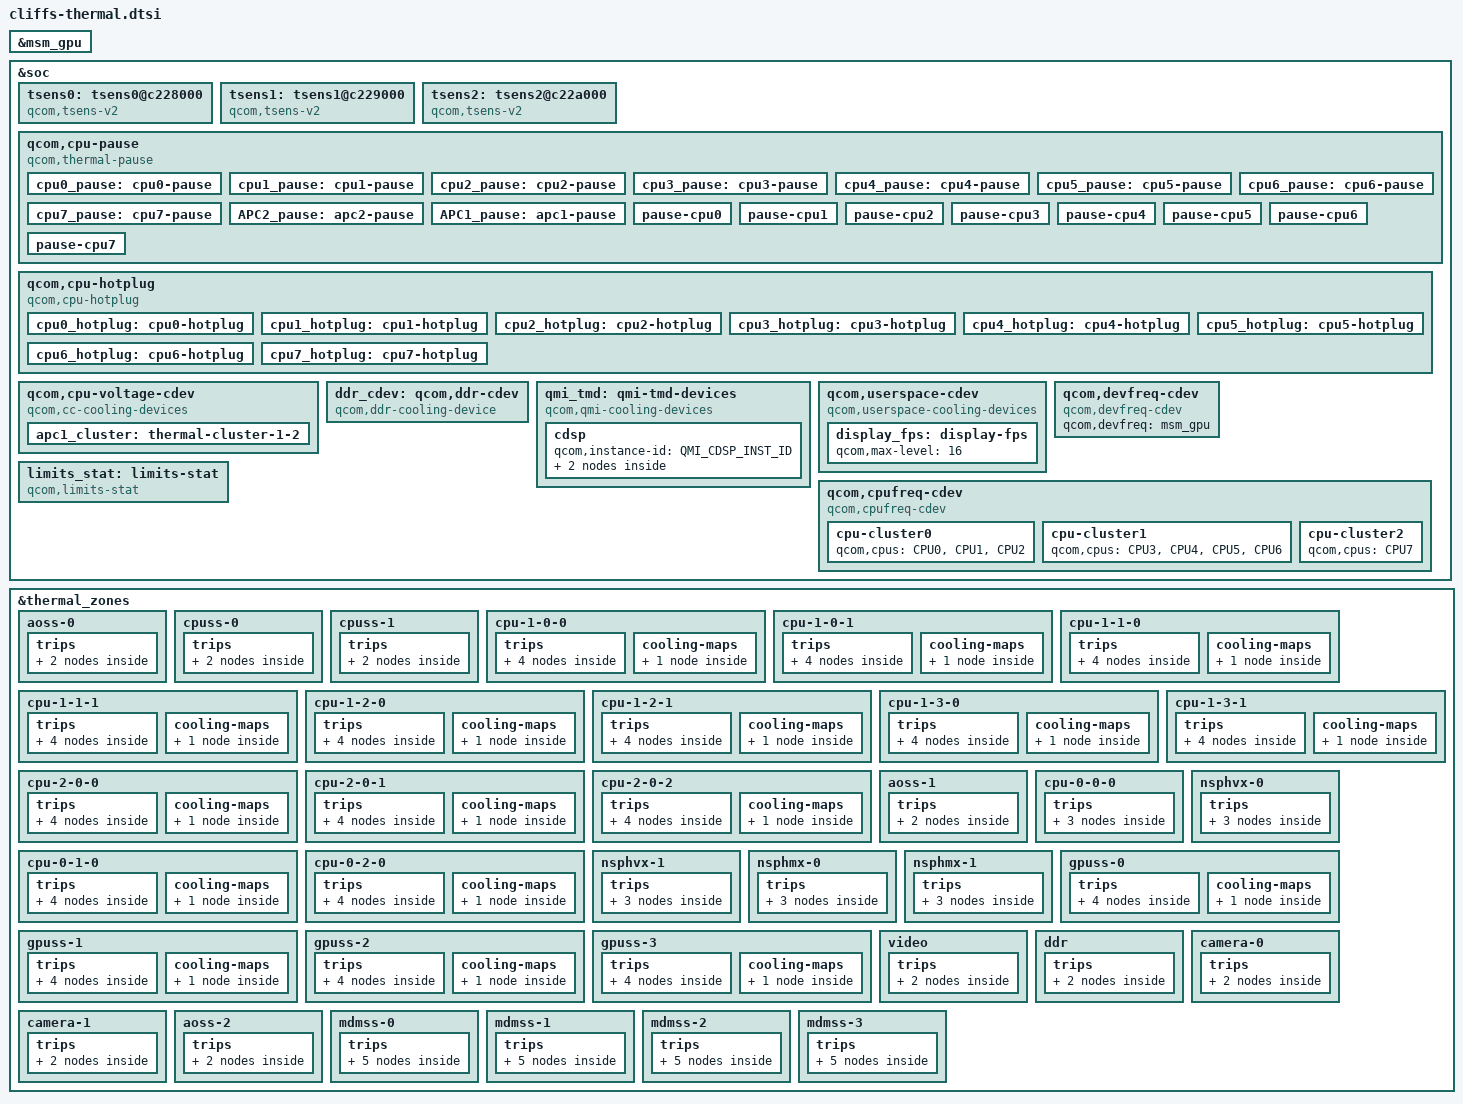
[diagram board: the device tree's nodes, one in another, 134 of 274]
#include <dt-bindings/thermal/thermal_qti.h>

&msm_gpu {
	#cooling-cells = <2>;
};

&soc {
	tsens0: tsens0@c228000 {
		compatible = "qcom,tsens-v2";
		reg = <0x0c228000 0x1ff>, /* TM */
		      <0x0c222000 0x1ff>; /* SROT */
		#qcom,sensors = <14>;
		interrupts = <GIC_SPI 506 IRQ_TYPE_LEVEL_HIGH>,
			     <GIC_SPI 640 IRQ_TYPE_LEVEL_HIGH>;
		interrupt-names = "uplow","critical";
		#thermal-sensor-cells = <1>;
	};

	tsens1: tsens1@c229000 {
		compatible = "qcom,tsens-v2";
		reg = <0x0c229000 0x1ff>, /* TM */
		      <0x0c223000 0x1ff>; /* SROT */
		#qcom,sensors = <16>;
		interrupts = <GIC_SPI 507 IRQ_TYPE_LEVEL_HIGH>,
			     <GIC_SPI 641 IRQ_TYPE_LEVEL_HIGH>;
		interrupt-names = "uplow","critical";
		#thermal-sensor-cells = <1>;
	};

	tsens2: tsens2@c22a000 {
		compatible = "qcom,tsens-v2";
		reg = <0x0c22a000 0x1ff>, /* TM */
		      <0x0c224000 0x1ff>; /* SROT */
		#qcom,sensors = <5>;
		interrupts = <GIC_SPI 508 IRQ_TYPE_LEVEL_HIGH>,
			     <GIC_SPI 642 IRQ_TYPE_LEVEL_HIGH>;
		interrupt-names = "uplow","critical";
		#thermal-sensor-cells = <1>;
	};

	qcom,cpu-pause {
		compatible = "qcom,thermal-pause";

		cpu0_pause: cpu0-pause {
			qcom,cpus = <&CPU0>;
			qcom,cdev-alias = "thermal-pause-1";
			#cooling-cells = <2>;
		};

		cpu1_pause: cpu1-pause {
			qcom,cpus = <&CPU1>;
			qcom,cdev-alias = "thermal-pause-2";
			#cooling-cells = <2>;
		};

		cpu2_pause: cpu2-pause {
			qcom,cpus = <&CPU2>;
			qcom,cdev-alias = "thermal-pause-4";
			#cooling-cells = <2>;
		};

		cpu3_pause: cpu3-pause {
			qcom,cpus = <&CPU3>;
			qcom,cdev-alias = "thermal-pause-8";
			#cooling-cells = <2>;
		};

		cpu4_pause: cpu4-pause {
			qcom,cpus = <&CPU4>;
			qcom,cdev-alias = "thermal-pause-10";
			#cooling-cells = <2>;
		};

		cpu5_pause: cpu5-pause {
			qcom,cpus = <&CPU5>;
			qcom,cdev-alias = "thermal-pause-20";
			#cooling-cells = <2>;
		};

		cpu6_pause: cpu6-pause {
			qcom,cpus = <&CPU6>;
			qcom,cdev-alias = "thermal-pause-40";
			#cooling-cells = <2>;
		};

		cpu7_pause: cpu7-pause {
			qcom,cpus = <&CPU7>;
			qcom,cdev-alias = "thermal-pause-80";
			#cooling-cells = <2>;
		};

		APC2_pause: apc2-pause {
			qcom,cpus = <&CPU2 &CPU3 &CPU4>;
			qcom,cdev-alias = "thermal-pause-1C";
			#cooling-cells = <2>;
		};

		APC1_pause: apc1-pause {
			qcom,cpus = <&CPU5 &CPU6 &CPU7>;
			qcom,cdev-alias = "thermal-pause-E0";
			#cooling-cells = <2>;
		};

		/* Thermal-engine cooling devices */
		pause-cpu0 {
			qcom,cpus = <&CPU0>;
			qcom,cdev-alias = "pause-cpu0";
		};

		pause-cpu1 {
			qcom,cpus = <&CPU1>;
			qcom,cdev-alias = "pause-cpu1";
		};

		pause-cpu2 {
			qcom,cpus = <&CPU2>;
			qcom,cdev-alias = "pause-cpu2";
		};

		pause-cpu3 {
			qcom,cpus = <&CPU3>;
			qcom,cdev-alias = "pause-cpu3";
		};

		pause-cpu4 {
			qcom,cpus = <&CPU4>;
			qcom,cdev-alias = "pause-cpu4";
		};

		pause-cpu5 {
			qcom,cpus = <&CPU5>;
			qcom,cdev-alias = "pause-cpu5";
		};

		pause-cpu6 {
			qcom,cpus = <&CPU6>;
			qcom,cdev-alias = "pause-cpu6";
		};

		pause-cpu7 {
			qcom,cpus = <&CPU7>;
			qcom,cdev-alias = "pause-cpu7";
		};
	};

	qcom,cpu-hotplug {
		compatible = "qcom,cpu-hotplug";

		cpu0_hotplug: cpu0-hotplug {
			qcom,cpu = <&CPU0>;
			qcom,cdev-alias = "cpu-hotplug0";
			#cooling-cells = <2>;
		};

		cpu1_hotplug: cpu1-hotplug {
			qcom,cpu = <&CPU1>;
			qcom,cdev-alias = "cpu-hotplug1";
			#cooling-cells = <2>;
		};

		cpu2_hotplug: cpu2-hotplug {
			qcom,cpu = <&CPU2>;
			qcom,cdev-alias = "cpu-hotplug2";
			#cooling-cells = <2>;
		};

		cpu3_hotplug: cpu3-hotplug {
			qcom,cpu = <&CPU3>;
			qcom,cdev-alias = "cpu-hotplug3";
			#cooling-cells = <2>;
		};

		cpu4_hotplug: cpu4-hotplug {
			qcom,cpu = <&CPU4>;
			qcom,cdev-alias = "cpu-hotplug4";
			#cooling-cells = <2>;
		};

		cpu5_hotplug: cpu5-hotplug {
			qcom,cpu = <&CPU5>;
			qcom,cdev-alias = "cpu-hotplug5";
			#cooling-cells = <2>;
		};

		cpu6_hotplug: cpu6-hotplug {
			qcom,cpu = <&CPU6>;
			qcom,cdev-alias = "cpu-hotplug6";
			#cooling-cells = <2>;
		};

		cpu7_hotplug: cpu7-hotplug {
			qcom,cpu = <&CPU7>;
			qcom,cdev-alias = "cpu-hotplug7";
			#cooling-cells = <2>;
		};
	};

	qcom,cpu-voltage-cdev {
		compatible = "qcom,cc-cooling-devices";
		apc1_cluster: thermal-cluster-1-2 {
			qcom,cluster0 = <&CPU3 &CPU4 &CPU5 &CPU6>;
			qcom,cluster1 = <&CPU7>;
			#cooling-cells = <2>;
		};
	};

	ddr_cdev: qcom,ddr-cdev {
		compatible = "qcom,ddr-cooling-device";
		#cooling-cells = <2>;
		qcom,bus-width = <4>;
		qcom,freq-table =
			< 547200 >,
			< 768000 >,
			< 1555200 >,
			< 1708800 >,
			< 2092800 >,
			< 2736000 >,
			< 3187200 >,
			< 3686400 >,
			< 4224000 >;
		interconnects = <&mc_virt MASTER_LLCC &mc_virt SLAVE_EBI1>;
	};

	qmi_tmd: qmi-tmd-devices {
		compatible = "qcom,qmi-cooling-devices";
		cdsp {
			qcom,instance-id = <QMI_CDSP_INST_ID>;

			cdsp_sw: cdsp {
				qcom,qmi-dev-name = "cdsp_sw";
				#cooling-cells = <2>;
			};

			cdsp_hw: cdsp_hw {
				qcom,qmi-dev-name = "cdsp_hw";
				#cooling-cells = <2>;
			};
		};
	};

	qcom,userspace-cdev {
		compatible = "qcom,userspace-cooling-devices";

		display_fps: display-fps {
			qcom,max-level = <16>;
			#cooling-cells = <2>;
		};
	};

	qcom,devfreq-cdev {
		compatible = "qcom,devfreq-cdev";
		qcom,devfreq = <&msm_gpu>;
	};

	qcom,cpufreq-cdev {
		compatible = "qcom,cpufreq-cdev";
		cpu-cluster0 {
			qcom,cpus = <&CPU0 &CPU1 &CPU2>;
		};

		cpu-cluster1 {
			qcom,cpus = <&CPU3 &CPU4 &CPU5 &CPU6>;
		};

		cpu-cluster2 {
			qcom,cpus = <&CPU7>;
		};
	};

	limits_stat: limits-stat {
		compatible = "qcom,limits-stat";
		qcom,limits-stat-sensor-names = "aoss-0", "cpuss-0", "cpuss-1",
						"cpu-1-0-0", "cpu-1-0-1", "cpu-1-1-0",
						"cpu-1-1-1", "cpu-1-2-0", "cpu-1-2-1",
						"cpu-1-3-0", "cpu-1-3-1", "cpu-2-0-0",
						"cpu-2-0-1", "cpu-2-0-2", "aoss-1",
						"cpu-0-0-0", "cpu-0-1-0", "cpu-0-2-0",
						"nsphvx-0", "nsphvx-1", "nsphmx-0",
						"nsphmx-1", "gpuss-0", "gpuss-1",
						"gpuss-2", "gpuss-3", "video",
						"ddr", "camera-0", "camera-1",
						"aoss-2", "mdmss-0", "mdmss-1",
						"mdmss-2", "mdmss-3", "vbat";
	};
};

#include "cliffs-thermal-modem.dtsi"

&thermal_zones {
	aoss-0 {
		polling-delay-passive = <0>;
		polling-delay = <0>;
		thermal-sensors = <&tsens0 0>;
		trips {
			thermal-engine-config {
				temperature = <125000>;
				hysteresis = <1000>;
				type = "passive";
			};

			reset-mon-cfg {
				temperature = <115000>;
				hysteresis = <5000>;
				type = "passive";
			};
		};
	};

	cpuss-0 {
		polling-delay-passive = <0>;
		polling-delay = <0>;
		thermal-sensors = <&tsens0 1>;
		trips {
			thermal-engine-config {
				temperature = <125000>;
				hysteresis = <1000>;
				type = "passive";
			};

			reset-mon-cfg {
				temperature = <115000>;
				hysteresis = <5000>;
				type = "passive";
			};
		};
	};

	cpuss-1 {
		polling-delay-passive = <0>;
		polling-delay = <0>;
		thermal-sensors = <&tsens0 2>;
		trips {
			thermal-engine-config {
				temperature = <125000>;
				hysteresis = <1000>;
				type = "passive";
			};

			reset-mon-cfg {
				temperature = <115000>;
				hysteresis = <5000>;
				type = "passive";
			};
		};
	};

	cpu-1-0-0 {
		polling-delay-passive = <10>;
		polling-delay = <0>;
		thermal-sensors = <&tsens0 3>;
		trips {
			thermal-engine-config {
				temperature = <125000>;
				hysteresis = <1000>;
				type = "passive";
			};

			thermal-hal-config {
				temperature = <125000>;
				hysteresis = <1000>;
				type = "passive";
			};

			cpu3_emerg0: cpu3-emerg0-cfg {
				temperature = <110000>;
				hysteresis = <10000>;
				type = "passive";
			};

			reset-mon-cfg {
				temperature = <115000>;
				hysteresis = <5000>;
				type = "passive";
			};
		};

		cooling-maps {
			cpu100_cdev {
				trip = <&cpu3_emerg0>;
				cooling-device = <&cpu3_pause 1 1>;
			};
		};
	};

	cpu-1-0-1 {
		polling-delay-passive = <10>;
		polling-delay = <0>;
		thermal-sensors = <&tsens0 4>;
		trips {
			thermal-engine-config {
				temperature = <125000>;
				hysteresis = <1000>;
				type = "passive";
			};

			thermal-hal-config {
				temperature = <125000>;
				hysteresis = <1000>;
				type = "passive";
			};

			cpu3_emerg1: cpu3-emerg1-cfg {
				temperature = <110000>;
				hysteresis = <10000>;
				type = "passive";
			};

			reset-mon-cfg {
				temperature = <115000>;
				hysteresis = <5000>;
				type = "passive";
			};
		};

		cooling-maps {
			cpu101_cdev {
				trip = <&cpu3_emerg1>;
				cooling-device = <&cpu3_pause 1 1>;
			};
		};
	};

	cpu-1-1-0 {
		polling-delay-passive = <10>;
		polling-delay = <0>;
		thermal-sensors = <&tsens0 5>;
		trips {
			thermal-engine-config {
				temperature = <125000>;
				hysteresis = <1000>;
				type = "passive";
			};

			thermal-hal-config {
				temperature = <125000>;
				hysteresis = <1000>;
				type = "passive";
			};

			cpu4_emerg0: cpu4-emerg0-cfg {
				temperature = <110000>;
				hysteresis = <10000>;
				type = "passive";
			};

			reset-mon-cfg {
				temperature = <115000>;
				hysteresis = <5000>;
				type = "passive";
			};
		};

		cooling-maps {
			cpu110_cdev {
				trip = <&cpu4_emerg0>;
				cooling-device = <&cpu4_pause 1 1>;
			};
		};
	};

	cpu-1-1-1 {
		polling-delay-passive = <10>;
		polling-delay = <0>;
		thermal-sensors = <&tsens0 6>;
		trips {
			thermal-engine-config {
				temperature = <125000>;
				hysteresis = <1000>;
				type = "passive";
			};

			thermal-hal-config {
				temperature = <125000>;
				hysteresis = <1000>;
				type = "passive";
			};

			cpu4_emerg1: cpu4-emerg1-cfg {
				temperature = <110000>;
				hysteresis = <10000>;
				type = "passive";
			};

			reset-mon-cfg {
				temperature = <115000>;
				hysteresis = <5000>;
				type = "passive";
			};
		};

		cooling-maps {
			cpu111_cdev {
				trip = <&cpu4_emerg1>;
				cooling-device = <&cpu4_pause 1 1>;
			};
		};
	};

	cpu-1-2-0 {
		polling-delay-passive = <10>;
		polling-delay = <0>;
		thermal-sensors = <&tsens0 7>;
		trips {
			thermal-engine-config {
				temperature = <125000>;
				hysteresis = <1000>;
				type = "passive";
			};

			thermal-hal-config {
				temperature = <125000>;
				hysteresis = <1000>;
				type = "passive";
			};

			cpu5_emerg0: cpu5-emerg0-cfg {
				temperature = <110000>;
				hysteresis = <10000>;
				type = "passive";
			};

			reset-mon-cfg {
				temperature = <115000>;
				hysteresis = <5000>;
				type = "passive";
			};
		};

		cooling-maps {
			cpu120_cdev {
				trip = <&cpu5_emerg0>;
				cooling-device = <&cpu5_pause 1 1>;
			};
		};
	};

	cpu-1-2-1 {
		polling-delay-passive = <10>;
		polling-delay = <0>;
		thermal-sensors = <&tsens0 8>;
		trips {
			thermal-engine-config {
				temperature = <125000>;
				hysteresis = <1000>;
				type = "passive";
			};

			thermal-hal-config {
				temperature = <125000>;
				hysteresis = <1000>;
				type = "passive";
			};

			cpu5_emerg1: cpu5-emerg1-cfg {
				temperature = <110000>;
				hysteresis = <10000>;
				type = "passive";
			};

			reset-mon-cfg {
				temperature = <115000>;
				hysteresis = <5000>;
				type = "passive";
			};
		};

		cooling-maps {
			cpu121_cdev {
				trip = <&cpu5_emerg1>;
				cooling-device = <&cpu5_pause 1 1>;
			};
		};
	};

	cpu-1-3-0 {
		polling-delay-passive = <10>;
		polling-delay = <0>;
		thermal-sensors = <&tsens0 9>;
		trips {
			thermal-engine-config {
				temperature = <125000>;
				hysteresis = <1000>;
				type = "passive";
			};

			thermal-hal-config {
				temperature = <125000>;
				hysteresis = <1000>;
				type = "passive";
			};

			cpu6_emerg0: cpu6-emerg0-cfg {
				temperature = <110000>;
				hysteresis = <10000>;
				type = "passive";
			};

			reset-mon-cfg {
				temperature = <115000>;
				hysteresis = <5000>;
				type = "passive";
			};
		};

		cooling-maps {
			cpu130_cdev {
				trip = <&cpu6_emerg0>;
				cooling-device = <&cpu6_pause 1 1>;
			};
		};
	};

	cpu-1-3-1 {
		polling-delay-passive = <10>;
		polling-delay = <0>;
		thermal-sensors = <&tsens0 10>;
		trips {
			thermal-engine-config {
				temperature = <125000>;
				hysteresis = <1000>;
				type = "passive";
			};

			thermal-hal-config {
				temperature = <125000>;
				hysteresis = <1000>;
				type = "passive";
			};

			cpu6_emerg1: cpu6-emerg1-cfg {
				temperature = <110000>;
				hysteresis = <10000>;
				type = "passive";
			};

			reset-mon-cfg {
				temperature = <115000>;
				hysteresis = <5000>;
				type = "passive";
			};
		};

		cooling-maps {
			cpu131_cdev {
				trip = <&cpu6_emerg1>;
				cooling-device = <&cpu6_pause 1 1>;
			};
		};
	};

	cpu-2-0-0 {
		polling-delay-passive = <10>;
		polling-delay = <0>;
		thermal-sensors = <&tsens0 11>;
		trips {
			thermal-engine-config {
				temperature = <125000>;
				hysteresis = <1000>;
				type = "passive";
			};

			thermal-hal-config {
				temperature = <125000>;
				hysteresis = <1000>;
				type = "passive";
			};

			cpu7_emerg0: cpu7-emerg0-cfg {
				temperature = <110000>;
				hysteresis = <10000>;
				type = "passive";
			};

			reset-mon-cfg {
				temperature = <115000>;
				hysteresis = <5000>;
				type = "passive";
			};
		};

		cooling-maps {
			cpu200_cdev {
				trip = <&cpu7_emerg0>;
				cooling-device = <&cpu7_pause 1 1>;
			};
		};
	};

	cpu-2-0-1 {
		polling-delay-passive = <10>;
		polling-delay = <0>;
		thermal-sensors = <&tsens0 12>;
		trips {
			thermal-engine-config {
				temperature = <125000>;
				hysteresis = <1000>;
				type = "passive";
			};

			thermal-hal-config {
				temperature = <125000>;
				hysteresis = <1000>;
				type = "passive";
			};

			cpu7_emerg1: cpu7-emerg1-cfg {
				temperature = <110000>;
				hysteresis = <10000>;
				type = "passive";
			};

			reset-mon-cfg {
				temperature = <115000>;
				hysteresis = <5000>;
				type = "passive";
			};
		};

		cooling-maps {
			cpu201_cdev {
				trip = <&cpu7_emerg1>;
				cooling-device = <&cpu7_pause 1 1>;
			};
		};
	};

	cpu-2-0-2 {
		polling-delay-passive = <10>;
		polling-delay = <0>;
		thermal-sensors = <&tsens0 13>;
		trips {
			thermal-engine-config {
				temperature = <125000>;
				hysteresis = <1000>;
				type = "passive";
			};

			thermal-hal-config {
				temperature = <125000>;
				hysteresis = <1000>;
				type = "passive";
			};

			cpu7_emerg2: cpu7-emerg2-cfg {
				temperature = <110000>;
				hysteresis = <10000>;
				type = "passive";
			};

			reset-mon-cfg {
				temperature = <115000>;
				hysteresis = <5000>;
				type = "passive";
			};
		};

		cooling-maps {
			cpu202_cdev {
				trip = <&cpu7_emerg2>;
				cooling-device = <&cpu7_pause 1 1>;
			};
		};
	};

	aoss-1 {
		polling-delay-passive = <0>;
		polling-delay = <0>;
		thermal-sensors = <&tsens1 0>;
		trips {
			thermal-engine-config {
				temperature = <125000>;
				hysteresis = <1000>;
				type = "passive";
			};

			reset-mon-cfg {
				temperature = <115000>;
				hysteresis = <5000>;
				type = "passive";
			};
		};
	};

	cpu-0-0-0 {
		polling-delay-passive = <10>;
		polling-delay = <0>;
		thermal-sensors = <&tsens1 1>;
		trips {
			thermal-engine-config {
				temperature = <125000>;
				hysteresis = <1000>;
				type = "passive";
			};

			thermal-hal-config {
				temperature = <125000>;
				hysteresis = <1000>;
				type = "passive";
			};

			reset-mon-cfg {
				temperature = <115000>;
				hysteresis = <5000>;
				type = "passive";
			};
		};
	};

	cpu-0-1-0 {
		polling-delay-passive = <10>;
		polling-delay = <0>;
		thermal-sensors = <&tsens1 2>;
		trips {
			thermal-engine-config {
				temperature = <125000>;
				hysteresis = <1000>;
				type = "passive";
			};

			thermal-hal-config {
				temperature = <125000>;
				hysteresis = <1000>;
				type = "passive";
			};

			cpu1_emerg0: cpu1-emerg0-cfg {
				temperature = <110000>;
				hysteresis = <8000>;
				type = "passive";
			};

			reset-mon-cfg {
				temperature = <115000>;
				hysteresis = <5000>;
				type = "passive";
			};
		};

		cooling-maps {
			cpu010_cdev {
				trip = <&cpu1_emerg0>;
				cooling-device = <&cpu1_pause 1 1>;
			};
		};
	};

	cpu-0-2-0 {
		polling-delay-passive = <10>;
		polling-delay = <0>;
		thermal-sensors = <&tsens1 3>;
		trips {
			thermal-engine-config {
				temperature = <125000>;
				hysteresis = <1000>;
				type = "passive";
			};

			thermal-hal-config {
				temperature = <125000>;
				hysteresis = <1000>;
				type = "passive";
			};

			cpu2_emerg0: cpu2-emerg0-cfg {
				temperature = <110000>;
				hysteresis = <8000>;
				type = "passive";
			};

			reset-mon-cfg {
				temperature = <115000>;
				hysteresis = <5000>;
				type = "passive";
			};
		};

		cooling-maps {
			cpu020_cdev {
				trip = <&cpu2_emerg0>;
				cooling-device = <&cpu2_pause 1 1>;
			};
		};
	};

	nsphvx-0 {
		polling-delay-passive = <10>;
		polling-delay = <0>;
		thermal-sensors = <&tsens1 4>;
		trips {
			thermal-engine-config {
				temperature = <125000>;
				hysteresis = <1000>;
				type = "passive";
			};

			thermal-hal-config {
				temperature = <125000>;
				hysteresis = <1000>;
				type = "passive";
			};

			reset-mon-cfg {
				temperature = <115000>;
				hysteresis = <5000>;
				type = "passive";
			};
		};
	};

	nsphvx-1 {
		polling-delay-passive = <10>;
		polling-delay = <0>;
		thermal-sensors = <&tsens1 5>;
		trips {
			thermal-engine-config {
				temperature = <125000>;
				hysteresis = <1000>;
				type = "passive";
			};

			thermal-hal-config {
				temperature = <125000>;
				hysteresis = <1000>;
				type = "passive";
			};

			reset-mon-cfg {
				temperature = <115000>;
				hysteresis = <5000>;
				type = "passive";
			};
		};
	};

	nsphmx-0 {
		polling-delay-passive = <10>;
		polling-delay = <0>;
		thermal-sensors = <&tsens1 6>;
		trips {
			thermal-engine-config {
				temperature = <125000>;
				hysteresis = <1000>;
				type = "passive";
			};

			thermal-hal-config {
				temperature = <125000>;
				hysteresis = <1000>;
				type = "passive";
			};

			reset-mon-cfg {
				temperature = <115000>;
				hysteresis = <5000>;
				type = "passive";
			};
		};
	};

	nsphmx-1 {
		polling-delay-passive = <10>;
		polling-delay = <0>;
		thermal-sensors = <&tsens1 7>;
		trips {
			thermal-engine-config {
				temperature = <125000>;
				hysteresis = <1000>;
				type = "passive";
			};

			thermal-hal-config {
				temperature = <125000>;
				hysteresis = <1000>;
				type = "passive";
			};

			reset-mon-cfg {
				temperature = <115000>;
				hysteresis = <5000>;
				type = "passive";
			};
		};
	};

	gpuss-0 {
		polling-delay-passive = <10>;
		polling-delay = <0>;
		thermal-sensors = <&tsens1 8>;
		trips {
			thermal-engine-config {
				temperature = <125000>;
				hysteresis = <1000>;
				type = "passive";
			};

			thermal-hal-config {
				temperature = <125000>;
				hysteresis = <1000>;
				type = "passive";
			};

			gpu0_tj_cfg: tj_cfg {
				temperature = <95000>;
				hysteresis = <5000>;
				type = "passive";
			};

			reset-mon-cfg {
				temperature = <115000>;
				hysteresis = <5000>;
				type = "passive";
			};
		};

		cooling-maps {
			gpu0_cdev {
				trip = <&gpu0_tj_cfg>;
				cooling-device = <&msm_gpu 0 THERMAL_NO_LIMIT>;
			};
		};
	};

	gpuss-1 {
		polling-delay-passive = <10>;
		polling-delay = <0>;
		thermal-sensors = <&tsens1 9>;
		trips {
			thermal-engine-config {
				temperature = <125000>;
				hysteresis = <1000>;
				type = "passive";
			};

			thermal-hal-config {
				temperature = <125000>;
				hysteresis = <1000>;
				type = "passive";
			};

			gpu1_tj_cfg: tj_cfg {
				temperature = <95000>;
				hysteresis = <5000>;
				type = "passive";
			};

			reset-mon-cfg {
				temperature = <115000>;
				hysteresis = <5000>;
				type = "passive";
			};
		};

		cooling-maps {
			gpu1_cdev {
				trip = <&gpu1_tj_cfg>;
				cooling-device = <&msm_gpu 0 THERMAL_NO_LIMIT>;
			};
		};
	};

	gpuss-2 {
		polling-delay-passive = <10>;
		polling-delay = <0>;
		thermal-sensors = <&tsens1 10>;
		trips {
			thermal-engine-config {
				temperature = <125000>;
				hysteresis = <1000>;
				type = "passive";
			};

			thermal-hal-config {
				temperature = <125000>;
				hysteresis = <1000>;
				type = "passive";
			};

			gpu2_tj_cfg: tj_cfg {
				temperature = <95000>;
				hysteresis = <5000>;
				type = "passive";
			};

			reset-mon-cfg {
				temperature = <115000>;
				hysteresis = <5000>;
				type = "passive";
			};
		};

		cooling-maps {
			gpu2_cdev {
				trip = <&gpu2_tj_cfg>;
				cooling-device = <&msm_gpu 0 THERMAL_NO_LIMIT>;
			};
		};
	};

	gpuss-3 {
		polling-delay-passive = <10>;
		polling-delay = <0>;
		thermal-sensors = <&tsens1 11>;
		trips {
			thermal-engine-config {
				temperature = <125000>;
				hysteresis = <1000>;
				type = "passive";
			};

			thermal-hal-config {
				temperature = <125000>;
				hysteresis = <1000>;
				type = "passive";
			};

			gpu3_tj_cfg: tj_cfg {
				temperature = <95000>;
				hysteresis = <5000>;
				type = "passive";
			};

			reset-mon-cfg {
				temperature = <115000>;
				hysteresis = <5000>;
				type = "passive";
			};
		};

		cooling-maps {
			gpu3_cdev {
				trip = <&gpu3_tj_cfg>;
				cooling-device = <&msm_gpu 0 THERMAL_NO_LIMIT>;
			};
		};
	};

	video {
		polling-delay-passive = <0>;
		polling-delay = <0>;
		thermal-sensors = <&tsens1 12>;
		trips {
			thermal-engine-config {
				temperature = <125000>;
				hysteresis = <1000>;
				type = "passive";
			};

			reset-mon-cfg {
				temperature = <115000>;
				hysteresis = <5000>;
				type = "passive";
			};
		};
	};

	ddr {
		polling-delay-passive = <10>;
		polling-delay = <0>;
		thermal-sensors = <&tsens1 13>;
		trips {
			thermal-engine-config {
				temperature = <125000>;
				hysteresis = <1000>;
				type = "passive";
			};

			reset-mon-cfg {
				temperature = <115000>;
				hysteresis = <5000>;
				type = "passive";
			};
		};
	};

	camera-0 {
		polling-delay-passive = <0>;
		polling-delay = <0>;
		thermal-sensors = <&tsens1 14>;
		trips {
			thermal-engine-config {
				temperature = <125000>;
				hysteresis = <1000>;
				type = "passive";
			};

			reset-mon-cfg {
				temperature = <115000>;
				hysteresis = <5000>;
				type = "passive";
			};
		};
	};

	camera-1 {
		polling-delay-passive = <0>;
		polling-delay = <0>;
		thermal-sensors = <&tsens1 15>;
		trips {
			thermal-engine-config {
				temperature = <125000>;
				hysteresis = <1000>;
				type = "passive";
			};

			reset-mon-cfg {
				temperature = <115000>;
				hysteresis = <5000>;
				type = "passive";
			};
		};
	};

	aoss-2 {
		polling-delay-passive = <0>;
		polling-delay = <0>;
		thermal-sensors = <&tsens2 0>;
		trips {
			thermal-engine-config {
				temperature = <125000>;
				hysteresis = <1000>;
				type = "passive";
			};

			reset-mon-cfg {
				temperature = <115000>;
				hysteresis = <5000>;
				type = "passive";
			};
		};
	};

	mdmss-0 {
		polling-delay-passive = <0>;
		polling-delay = <0>;
		thermal-sensors = <&tsens2 1>;
		trips {
			thermal-engine-config {
				temperature = <125000>;
				hysteresis = <1000>;
				type = "passive";
			};

			thermal-hal-config {
				temperature = <125000>;
				hysteresis = <1000>;
				type = "passive";
			};

			mdmss0_config0: mdmss0-config0 {
				temperature = <102000>;
				hysteresis = <3000>;
				type = "passive";
			};

			mdmss0_config1: mdmss0-config1 {
				temperature = <105000>;
				hysteresis = <3000>;
				type = "passive";
			};

			reset-mon-cfg {
				temperature = <115000>;
				hysteresis = <5000>;
				type = "passive";
			};
		};
	};

	mdmss-1 {
		polling-delay-passive = <0>;
		polling-delay = <0>;
		thermal-sensors = <&tsens2 2>;
		trips {
			thermal-engine-config {
				temperature = <125000>;
				hysteresis = <1000>;
				type = "passive";
			};

			thermal-hal-config {
				temperature = <125000>;
				hysteresis = <1000>;
				type = "passive";
			};

			mdmss1_config0: mdmss1-config0 {
				temperature = <102000>;
				hysteresis = <3000>;
				type = "passive";
			};

			mdmss1_config1: mdmss1-config1 {
				temperature = <105000>;
				hysteresis = <3000>;
				type = "passive";
			};

			reset-mon-cfg {
				temperature = <115000>;
				hysteresis = <5000>;
				type = "passive";
			};
		};
	};

	mdmss-2 {
		polling-delay-passive = <0>;
		polling-delay = <0>;
		thermal-sensors = <&tsens2 3>;
		trips {
			thermal-engine-config {
				temperature = <125000>;
				hysteresis = <1000>;
				type = "passive";
			};

			thermal-hal-config {
				temperature = <125000>;
				hysteresis = <1000>;
				type = "passive";
			};

			mdmss2_config0: mdmss2-config0 {
				temperature = <102000>;
				hysteresis = <3000>;
				type = "passive";
			};

			mdmss2_config1: mdmss2-config1 {
				temperature = <105000>;
				hysteresis = <3000>;
				type = "passive";
			};

			reset-mon-cfg {
				temperature = <115000>;
				hysteresis = <5000>;
				type = "passive";
			};
		};
	};

	mdmss-3 {
		polling-delay-passive = <0>;
		polling-delay = <0>;
		thermal-sensors = <&tsens2 4>;
		trips {
			thermal-engine-config {
				temperature = <125000>;
				hysteresis = <1000>;
				type = "passive";
			};

			thermal-hal-config {
				temperature = <125000>;
				hysteresis = <1000>;
				type = "passive";
			};

			mdmss3_config0: mdmss3-config0 {
				temperature = <102000>;
				hysteresis = <3000>;
				type = "passive";
			};

			mdmss3_config1: mdmss3-config1 {
				temperature = <105000>;
				hysteresis = <3000>;
				type = "passive";
			};

			reset-mon-cfg {
				temperature = <115000>;
				hysteresis = <5000>;
				type = "passive";
			};
		};
	};
};
